VERSION ""

NS_ :

BS_:

BU_:

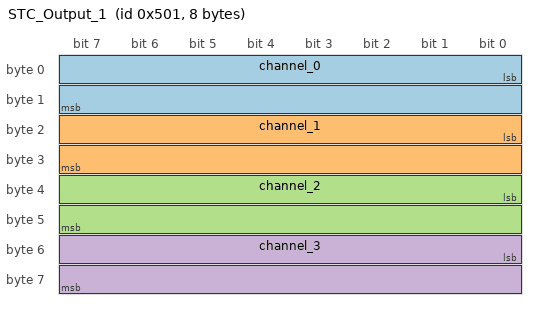
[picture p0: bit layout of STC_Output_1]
BO_ 1281 STC_Output_1: 8 Vector__XXX
	SG_ channel_0 : 0|16@1+ (1,0) [0|65535] "mV" Vector__XXX
	SG_ channel_1 : 16|16@1+ (1,0) [0|65535] "mV" Vector__XXX
	SG_ channel_2 : 32|16@1+ (1,0) [0|65535] "mV" Vector__XXX
	SG_ channel_3 : 48|16@1+ (1,0) [0|65535] "mV" Vector__XXX

BO_ 1282 STC_Output: 8 Vector__XXX
	SG_ channel_4 : 0|16@1+ (1,0) [0|65535] "mV" Vector__XXX

BO_ 1283 STC_Device_Status: 8 Vector__XXX
	SG_ adc_status M : 0|16@1+ (1,0) [0|65535] "" Vector__XXX
	SG_ uptime : 16|16@1+ (1,0) [0|65535] "mS" Vector__XXX
	SG_ v_supply : 32|16@1+ (1,0) [0|65535] "mV" Vector__XXX
	SG_ fw_version : 48|16@1+ (1,0) [0|65535] "" Vector__XXX
	SG_ channel_5 : 16|16@1+ (1,0) [0|65535] "mV" Vector__XXX
	SG_ channel_6 : 32|16@1+ (1,0) [0|65535] "mV" Vector__XXX
	SG_ channel_7 : 48|16@1+ (1,0) [0|65535] "mV" Vector__XXX

CM_ BO_ 1281 "ADC Values 0 to 3";
CM_ SG_ 1281 channel_0 "Channel 1 Input Voltage";
CM_ BO_ 1282 "ADC Values 4 to 7";
CM_ SG_ 1282 channel_4 "Channel 4 Input Voltage";
CM_ BO_ 1283 "Device and channel status";
CM_ SG_ 1283 adc_status "Byte mask of each 2-bit ADC status";
CM_ SG_ 1283 uptime "Up time of device in milliseconds. Wraps.";
CM_ SG_ 1283 v_supply "Supply voltage in millivolts";
CM_ SG_ 1283 fw_version "Firmware version";
BA_DEF_ SG_  "SPN" INT 0 524287;
BA_DEF_ BO_  "VFrameFormat" ENUM  "StandardCAN","ExtendedCAN","reserved","J1939PG";
BA_DEF_  "DatabaseVersion" STRING ;
BA_DEF_  "BusType" STRING ;
BA_DEF_  "ProtocolType" STRING ;
BA_DEF_  "DatabaseCompiler" STRING ;
BA_DEF_DEF_  "SPN" 0;
BA_DEF_DEF_  "VFrameFormat" "J1939PG";
BA_DEF_DEF_  "DatabaseVersion" "DEMO PLUS";
BA_DEF_DEF_  "BusType" "";
BA_DEF_DEF_  "ProtocolType" "";
BA_DEF_DEF_  "DatabaseCompiler" "";
BA_ "ProtocolType" "J1939";
BA_ "BusType" "CAN";
BA_ "DatabaseCompiler" "CSS ELECTRONICS (WWW.CSSELECTRONICS.COM)";
BA_ "DatabaseVersion" "1.0.0";
BA_ "SPN" SG_ 1281 EngineSpeed 190;
BA_ "SPN" SG_ 1282 WheelBasedVehicleSpeed 84;
